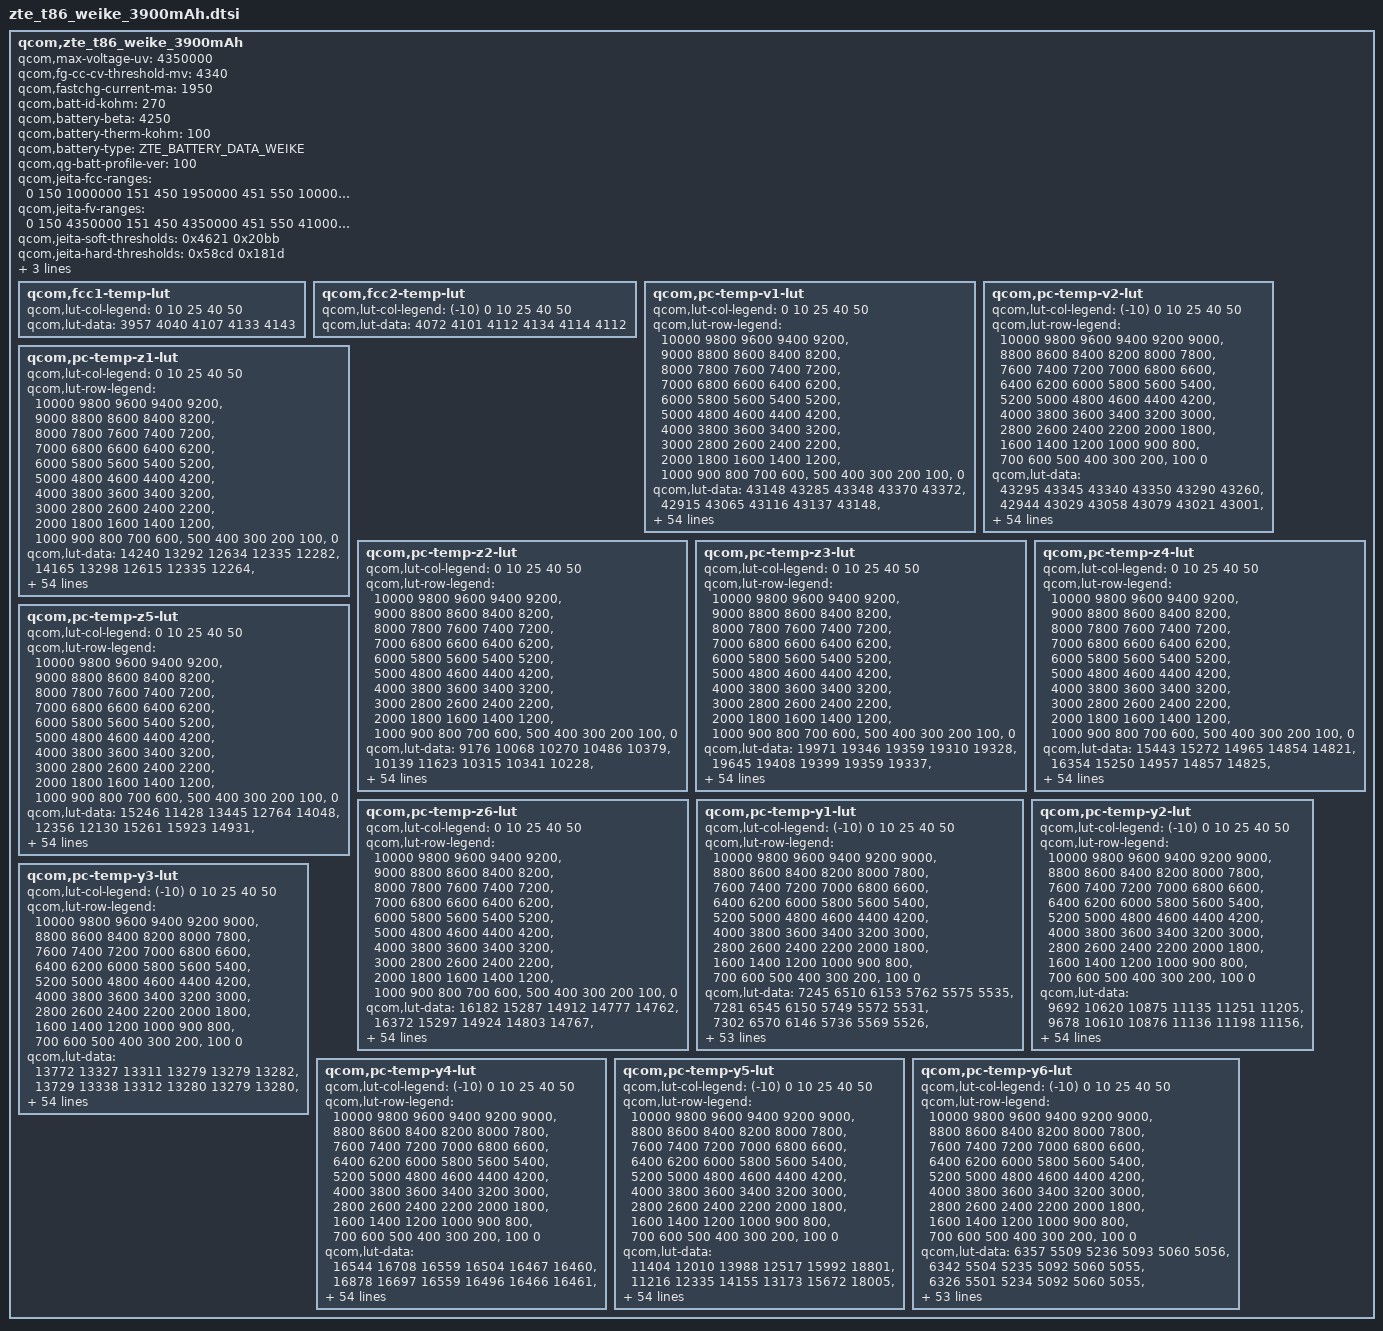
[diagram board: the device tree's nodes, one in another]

qcom,zte_t86_weike_3900mAh {
	/* 4170286_ZTE_T86_3990mAH_PMI632_averaged_MasterSlave_Aug27th2019 */
	qcom,max-voltage-uv = <4350000>;
	qcom,fg-cc-cv-threshold-mv = <4340>;
	qcom,fastchg-current-ma = <1950>;
	qcom,batt-id-kohm = <270>;
	qcom,battery-beta = <4250>;
	qcom,battery-therm-kohm = <100>;
	qcom,battery-type = "ZTE_BATTERY_DATA_WEIKE";
	qcom,qg-batt-profile-ver = <100>;

	qcom,jeita-fcc-ranges = <0   150   1000000
				 151 450  1950000
				 451 550  1000000>;
	qcom,jeita-fv-ranges =  <0   150  4350000
				 151 450  4350000
				 451 550  4100000>;

	/* COOL = 15 DegC, WARM = 45 DegC */
	qcom,jeita-soft-thresholds = <0x4621 0x20bb>;
	/* COLD = 0 DegC, HOT = 55 DegC */
	qcom,jeita-hard-thresholds = <0x58cd 0x181d>;
	/* COOL hys = 17 DegC, WARM hys = 43 DegC */
	qcom,jeita-soft-hys-thresholds = <0x4365 0x22b8>;
	qcom,jeita-soft-fcc-ua = <1000000 1000000>;
	qcom,jeita-soft-fv-uv = <4350000 4100000>;

	qcom,fcc1-temp-lut {
		qcom,lut-col-legend = <0 10 25 40 50>;
		qcom,lut-data = <3957 4040 4107 4133 4143>;
	};

	qcom,fcc2-temp-lut {
		qcom,lut-col-legend = <(-10) 0 10 25 40 50>;
		qcom,lut-data = <4072 4101 4112 4134 4114 4112>;
	};

	qcom,pc-temp-v1-lut {
		qcom,lut-col-legend = <0 10 25 40 50>;
		qcom,lut-row-legend = <10000 9800 9600 9400 9200>,
			<9000 8800 8600 8400 8200>,
			<8000 7800 7600 7400 7200>,
			<7000 6800 6600 6400 6200>,
			<6000 5800 5600 5400 5200>,
			<5000 4800 4600 4400 4200>,
			<4000 3800 3600 3400 3200>,
			<3000 2800 2600 2400 2200>,
			<2000 1800 1600 1400 1200>,
			<1000 900 800 700 600>,
			<500 400 300 200 100>,
			<0>;
		qcom,lut-data = <43148 43285 43348 43370 43372>,
			<42915 43065 43116 43137 43148>,
			<42660 42817 42879 42905 42919>,
			<42429 42577 42644 42677 42689>,
			<42213 42343 42420 42451 42463>,
			<42007 42124 42200 42225 42239>,
			<41804 41919 41978 42002 42017>,
			<41601 41713 41758 41782 41798>,
			<41408 41499 41543 41567 41581>,
			<41242 41301 41330 41354 41367>,
			<41086 41142 41139 41147 41158>,
			<40883 40990 40978 40947 40956>,
			<40598 40767 40802 40750 40759>,
			<40319 40458 40547 40555 40567>,
			<40102 40203 40268 40361 40379>,
			<39921 40028 40089 40182 40199>,
			<39783 39884 39965 40019 40029>,
			<39676 39761 39839 39863 39866>,
			<39574 39654 39702 39717 39718>,
			<39463 39536 39557 39570 39574>,
			<39350 39402 39403 39393 39402>,
			<39236 39256 39236 39187 39200>,
			<39118 39084 39041 38996 39010>,
			<39004 38894 38796 38819 38835>,
			<38898 38731 38621 38670 38683>,
			<38797 38579 38533 38564 38568>,
			<38700 38468 38466 38476 38473>,
			<38604 38393 38395 38389 38384>,
			<38518 38336 38326 38304 38300>,
			<38443 38290 38263 38229 38224>,
			<38378 38250 38206 38165 38155>,
			<38325 38215 38154 38108 38091>,
			<38280 38182 38109 38057 38035>,
			<38240 38152 38068 38010 37982>,
			<38205 38125 38031 37963 37930>,
			<38170 38098 37996 37917 37876>,
			<38135 38066 37958 37870 37820>,
			<38099 38029 37916 37823 37766>,
			<38051 37980 37864 37769 37704>,
			<37981 37901 37787 37691 37622>,
			<37890 37796 37680 37585 37518>,
			<37771 37677 37564 37468 37401>,
			<37627 37537 37430 37332 37264>,
			<37472 37383 37280 37185 37117>,
			<37333 37243 37140 37047 36983>,
			<37233 37153 37055 36968 36910>,
			<37197 37125 37034 36946 36888>,
			<37172 37106 37018 36929 36870>,
			<37144 37086 37000 36913 36852>,
			<37104 37050 36957 36860 36790>,
			<36926 36852 36738 36613 36526>,
			<36510 36434 36312 36174 36081>,
			<35942 35869 35743 35602 35508>,
			<35174 35101 34967 34819 34724>,
			<33972 33914 33761 33611 33510>,
			<30000 30000 30000 30000 30000>;
	};

	qcom,pc-temp-v2-lut {
		qcom,lut-col-legend = <(-10) 0 10 25 40 50>;
		qcom,lut-row-legend = <10000 9800 9600 9400 9200 9000>,
			<8800 8600 8400 8200 8000 7800>,
			<7600 7400 7200 7000 6800 6600>,
			<6400 6200 6000 5800 5600 5400>,
			<5200 5000 4800 4600 4400 4200>,
			<4000 3800 3600 3400 3200 3000>,
			<2800 2600 2400 2200 2000 1800>,
			<1600 1400 1200 1000 900 800>,
			<700 600 500 400 300 200>,
			<100 0>;
		qcom,lut-data = <43295 43345 43340 43350 43290 43260>,
			<42944 43029 43058 43079 43021 43001>,
			<42626 42740 42794 42821 42766 42753>,
			<42343 42481 42549 42580 42526 42517>,
			<42092 42247 42322 42353 42300 42292>,
			<41850 42024 42100 42130 42077 42070>,
			<41609 41809 41881 41906 41855 41848>,
			<41386 41599 41667 41687 41637 41630>,
			<41201 41383 41453 41471 41422 41415>,
			<41037 41171 41243 41260 41210 41203>,
			<40874 40999 41056 41056 41003 40996>,
			<40724 40867 40891 40860 40801 40793>,
			<40527 40697 40700 40655 40603 40596>,
			<40122 40398 40437 40427 40410 40405>,
			<39669 40067 40168 40212 40223 40220>,
			<39451 39829 39965 40036 40048 40045>,
			<39321 39633 39793 39882 39883 39877>,
			<39185 39458 39627 39736 39726 39717>,
			<39026 39304 39470 39601 39580 39569>,
			<38869 39155 39305 39444 39422 39410>,
			<38722 38989 39108 39230 39226 39219>,
			<38581 38826 38909 39005 39017 39015>,
			<38454 38682 38750 38817 38827 38827>,
			<38333 38553 38614 38647 38647 38646>,
			<38233 38435 38494 38514 38506 38503>,
			<38157 38325 38388 38407 38398 38395>,
			<38093 38226 38292 38312 38305 38302>,
			<38036 38135 38203 38223 38217 38212>,
			<37984 38052 38122 38142 38136 38130>,
			<37937 37982 38048 38070 38064 38055>,
			<37892 37921 37982 38005 37999 37987>,
			<37849 37871 37919 37943 37937 37924>,
			<37805 37833 37859 37884 37884 37871>,
			<37761 37799 37804 37826 37827 37815>,
			<37712 37765 37761 37771 37760 37740>,
			<37660 37731 37724 37715 37683 37648>,
			<37604 37690 37682 37653 37602 37554>,
			<37544 37642 37635 37588 37513 37452>,
			<37479 37584 37579 37520 37429 37360>,
			<37408 37515 37513 37452 37358 37288>,
			<37330 37435 37435 37374 37282 37213>,
			<37248 37338 37335 37280 37192 37121>,
			<37165 37214 37217 37161 37075 37002>,
			<37079 37094 37076 37027 36945 36868>,
			<36980 36991 36961 36904 36827 36765>,
			<36876 36911 36919 36872 36800 36743>,
			<36821 36878 36898 36863 36789 36733>,
			<36755 36839 36878 36843 36774 36716>,
			<36666 36785 36842 36814 36748 36682>,
			<36528 36676 36744 36720 36654 36553>,
			<36279 36444 36441 36406 36333 36178>,
			<35859 35991 35918 35893 35830 35658>,
			<35232 35337 35230 35217 35178 34975>,
			<34302 34419 34257 34250 34253 34004>,
			<32614 32924 32845 32827 32895 32598>,
			<29817 28642 28556 28034 28094 28150>;
	};

	qcom,pc-temp-z1-lut {
		qcom,lut-col-legend = <0 10 25 40 50>;
		qcom,lut-row-legend = <10000 9800 9600 9400 9200>,
			<9000 8800 8600 8400 8200>,
			<8000 7800 7600 7400 7200>,
			<7000 6800 6600 6400 6200>,
			<6000 5800 5600 5400 5200>,
			<5000 4800 4600 4400 4200>,
			<4000 3800 3600 3400 3200>,
			<3000 2800 2600 2400 2200>,
			<2000 1800 1600 1400 1200>,
			<1000 900 800 700 600>,
			<500 400 300 200 100>,
			<0>;
		qcom,lut-data = <14240 13292 12634 12335 12282>,
			<14165 13298 12615 12335 12264>,
			<14177 13295 12593 12331 12258>,
			<14185 13277 12581 12325 12262>,
			<14174 13251 12579 12323 12261>,
			<14158 13249 12575 12323 12260>,
			<14145 13249 12569 12323 12262>,
			<14137 13248 12565 12323 12264>,
			<14133 13237 12566 12324 12268>,
			<14147 13227 12569 12326 12274>,
			<14165 13220 12572 12328 12278>,
			<14158 13209 12572 12329 12276>,
			<14088 13185 12570 12330 12274>,
			<14007 13131 12554 12329 12274>,
			<13959 13107 12533 12327 12274>,
			<13927 13109 12532 12327 12274>,
			<13927 13113 12542 12327 12273>,
			<13941 13126 12551 12327 12272>,
			<13951 13149 12556 12328 12272>,
			<13961 13164 12560 12329 12272>,
			<13973 13179 12562 12328 12273>,
			<13972 13189 12564 12327 12275>,
			<13954 13189 12565 12326 12275>,
			<13951 13188 12568 12327 12275>,
			<13971 13192 12570 12329 12275>,
			<13989 13202 12572 12330 12277>,
			<13989 13208 12576 12333 12280>,
			<13986 13206 12579 12337 12282>,
			<13985 13203 12584 12341 12284>,
			<13984 13208 12589 12345 12285>,
			<13985 13218 12592 12347 12287>,
			<14002 13227 12596 12349 12289>,
			<14041 13237 12601 12352 12291>,
			<14055 13245 12607 12355 12293>,
			<14046 13254 12613 12359 12296>,
			<14037 13267 12619 12363 12299>,
			<14039 13280 12626 12366 12301>,
			<14049 13295 12633 12369 12303>,
			<14063 13306 12639 12371 12304>,
			<14097 13313 12644 12372 12305>,
			<14123 13320 12649 12374 12307>,
			<14126 13329 12652 12376 12307>,
			<14128 13344 12656 12378 12309>,
			<14139 13368 12659 12379 12310>,
			<14150 13378 12662 12378 12311>,
			<14171 13346 12665 12377 12305>,
			<14140 13345 12662 12377 12304>,
			<14126 13343 12664 12378 12305>,
			<14121 13348 12672 12380 12307>,
			<14135 13355 12675 12383 12309>,
			<14176 13390 12682 12388 12313>,
			<14179 13408 12691 12396 12318>,
			<14189 13408 12708 12404 12327>,
			<14207 13464 12730 12418 12339>,
			<14207 13464 12730 12418 12339>,
			<14207 13464 12730 12418 12339>;
	};

	qcom,pc-temp-z2-lut {
		qcom,lut-col-legend = <0 10 25 40 50>;
		qcom,lut-row-legend = <10000 9800 9600 9400 9200>,
			<9000 8800 8600 8400 8200>,
			<8000 7800 7600 7400 7200>,
			<7000 6800 6600 6400 6200>,
			<6000 5800 5600 5400 5200>,
			<5000 4800 4600 4400 4200>,
			<4000 3800 3600 3400 3200>,
			<3000 2800 2600 2400 2200>,
			<2000 1800 1600 1400 1200>,
			<1000 900 800 700 600>,
			<500 400 300 200 100>,
			<0>;
		qcom,lut-data = <9176 10068 10270 10486 10379>,
			<10139 11623 10315 10341 10228>,
			<9947 10936 10345 10348 10191>,
			<9982 10589 10453 10412 10296>,
			<9986 10158 10710 10407 10340>,
			<9986 10153 10868 10398 10378>,
			<9987 10272 10817 10384 10378>,
			<9991 10303 10739 10370 10351>,
			<9994 10165 10707 10363 10332>,
			<9984 10048 10691 10315 10316>,
			<9969 10094 10673 10281 10294>,
			<9962 10187 10654 10285 10234>,
			<9955 10194 10627 10292 10165>,
			<9946 10113 10538 10283 10167>,
			<9936 10065 10393 10258 10203>,
			<9923 10069 10333 10248 10226>,
			<9915 10078 10293 10238 10234>,
			<9909 10091 10280 10232 10242>,
			<9906 10113 10309 10242 10257>,
			<9904 10132 10346 10269 10276>,
			<9904 10150 10372 10345 10314>,
			<9906 10164 10401 10517 10422>,
			<9907 10178 10402 10568 10473>,
			<9909 10190 10360 10414 10415>,
			<9914 10190 10330 10285 10355>,
			<9923 10188 10330 10322 10379>,
			<9933 10187 10341 10397 10435>,
			<9946 10200 10358 10428 10424>,
			<9957 10216 10382 10454 10301>,
			<9964 10219 10396 10439 10228>,
			<9970 10220 10396 10365 10189>,
			<9976 10220 10392 10285 10151>,
			<9982 10220 10385 10233 10144>,
			<9986 10222 10376 10193 10146>,
			<9991 10232 10378 10198 10162>,
			<9998 10245 10389 10258 10223>,
			<10006 10255 10404 10305 10285>,
			<10017 10263 10432 10345 10344>,
			<10028 10272 10464 10378 10389>,
			<10039 10285 10494 10386 10396>,
			<10050 10298 10519 10397 10393>,
			<10057 10303 10522 10415 10392>,
			<10065 10307 10510 10459 10393>,
			<10096 10314 10511 10459 10393>,
			<10062 10357 10521 10436 10394>,
			<9882 10490 10540 10439 10387>,
			<9866 10519 10511 10447 10375>,
			<9744 10699 10508 10427 10376>,
			<9847 10807 10528 10455 10436>,
			<9841 10897 10559 10566 10501>,
			<9713 10618 10614 10457 10333>,
			<9664 10574 10591 10308 10167>,
			<9647 10516 10501 10241 10099>,
			<9614 10351 10448 10172 10035>,
			<9614 10351 10448 10172 10035>,
			<9614 10351 10448 10172 10035>;
	};

	qcom,pc-temp-z3-lut {
		qcom,lut-col-legend = <0 10 25 40 50>;
		qcom,lut-row-legend = <10000 9800 9600 9400 9200>,
			<9000 8800 8600 8400 8200>,
			<8000 7800 7600 7400 7200>,
			<7000 6800 6600 6400 6200>,
			<6000 5800 5600 5400 5200>,
			<5000 4800 4600 4400 4200>,
			<4000 3800 3600 3400 3200>,
			<3000 2800 2600 2400 2200>,
			<2000 1800 1600 1400 1200>,
			<1000 900 800 700 600>,
			<500 400 300 200 100>,
			<0>;
		qcom,lut-data = <19971 19346 19359 19310 19328>,
			<19645 19408 19399 19359 19337>,
			<19767 19525 19416 19368 19348>,
			<19812 19576 19457 19398 19382>,
			<19807 19620 19462 19405 19393>,
			<19794 19628 19465 19409 19398>,
			<19790 19629 19469 19410 19400>,
			<19787 19629 19471 19411 19402>,
			<19783 19623 19474 19411 19402>,
			<19777 19617 19476 19404 19400>,
			<19763 19611 19475 19398 19396>,
			<19763 19605 19462 19392 19389>,
			<19798 19606 19449 19386 19379>,
			<19826 19604 19450 19383 19375>,
			<19814 19596 19452 19381 19372>,
			<19785 19578 19440 19378 19370>,
			<19756 19557 19414 19371 19366>,
			<19725 19537 19402 19364 19363>,
			<19701 19517 19403 19360 19356>,
			<19687 19512 19405 19358 19348>,
			<19678 19516 19409 19362 19350>,
			<19676 19522 19418 19378 19360>,
			<19686 19532 19422 19382 19365>,
			<19696 19545 19421 19366 19351>,
			<19702 19551 19418 19350 19337>,
			<19709 19553 19411 19351 19349>,
			<19713 19553 19405 19359 19375>,
			<19718 19551 19406 19370 19385>,
			<19721 19548 19413 19392 19389>,
			<19721 19545 19418 19401 19388>,
			<19719 19542 19424 19397 19384>,
			<19715 19539 19427 19391 19378>,
			<19707 19534 19426 19386 19373>,
			<19698 19530 19424 19380 19367>,
			<19689 19526 19422 19375 19361>,
			<19677 19520 19418 19369 19354>,
			<19657 19516 19415 19365 19349>,
			<19628 19511 19413 19362 19347>,
			<19608 19507 19410 19359 19346>,
			<19592 19504 19408 19358 19346>,
			<19583 19502 19405 19358 19346>,
			<19589 19500 19403 19358 19348>,
			<19595 19498 19401 19361 19352>,
			<19582 19494 19399 19361 19354>,
			<19494 19477 19394 19357 19354>,
			<19316 19406 19381 19347 19341>,
			<19309 19365 19373 19343 19334>,
			<19274 19321 19362 19340 19331>,
			<19297 19305 19358 19331 19320>,
			<19273 19301 19354 19324 19316>,
			<19274 19347 19349 19342 19343>,
			<19277 19350 19348 19356 19352>,
			<19321 19341 19355 19359 19354>,
			<19324 19334 19355 19359 19359>,
			<19324 19334 19355 19359 19359>,
			<19324 19334 19355 19359 19359>;
	};

	qcom,pc-temp-z4-lut {
		qcom,lut-col-legend = <0 10 25 40 50>;
		qcom,lut-row-legend = <10000 9800 9600 9400 9200>,
			<9000 8800 8600 8400 8200>,
			<8000 7800 7600 7400 7200>,
			<7000 6800 6600 6400 6200>,
			<6000 5800 5600 5400 5200>,
			<5000 4800 4600 4400 4200>,
			<4000 3800 3600 3400 3200>,
			<3000 2800 2600 2400 2200>,
			<2000 1800 1600 1400 1200>,
			<1000 900 800 700 600>,
			<500 400 300 200 100>,
			<0>;
		qcom,lut-data = <15443 15272 14965 14854 14821>,
			<16354 15250 14957 14857 14825>,
			<16318 15431 14896 14811 14800>,
			<16199 15330 14994 14885 14855>,
			<16037 15199 14928 14860 14839>,
			<15850 15100 14862 14823 14806>,
			<15706 15006 14824 14798 14784>,
			<15594 14952 14793 14776 14765>,
			<15491 14924 14767 14758 14748>,
			<15388 14897 14745 14743 14731>,
			<15293 14850 14725 14731 14719>,
			<15218 14791 14704 14722 14715>,
			<15157 14774 14692 14714 14712>,
			<15107 14784 14705 14708 14706>,
			<15065 14787 14730 14703 14699>,
			<15028 14771 14731 14698 14692>,
			<14996 14755 14716 14693 14686>,
			<14967 14746 14702 14687 14681>,
			<14944 14739 14691 14681 14677>,
			<14925 14732 14684 14676 14674>,
			<14909 14723 14687 14683 14680>,
			<14890 14716 14697 14715 14713>,
			<14867 14733 14725 14754 14751>,
			<14847 14772 14815 14812 14802>,
			<14832 14794 14864 14848 14836>,
			<14818 14829 14853 14837 14817>,
			<14809 14845 14833 14809 14771>,
			<14805 14837 14811 14780 14744>,
			<14802 14823 14786 14742 14723>,
			<14798 14809 14763 14718 14710>,
			<14795 14789 14742 14707 14701>,
			<14790 14772 14724 14700 14694>,
			<14783 14757 14712 14693 14688>,
			<14775 14744 14703 14687 14683>,
			<14767 14731 14697 14687 14682>,
			<14761 14720 14693 14690 14686>,
			<14763 14712 14691 14691 14689>,
			<14771 14704 14690 14691 14691>,
			<14776 14701 14689 14690 14693>,
			<14776 14702 14692 14694 14697>,
			<14773 14703 14699 14703 14702>,
			<14762 14702 14699 14704 14703>,
			<14748 14698 14694 14698 14699>,
			<14748 14696 14693 14698 14699>,
			<14800 14694 14690 14701 14701>,
			<14934 14714 14660 14670 14671>,
			<14937 14755 14658 14663 14666>,
			<14966 14797 14655 14647 14649>,
			<14936 14808 14648 14638 14637>,
			<14953 14807 14651 14641 14637>,
			<14952 14766 14678 14654 14649>,
			<14972 14777 14693 14656 14657>,
			<14941 14797 14690 14658 14660>,
			<14960 14820 14696 14662 14657>,
			<14960 14820 14696 14662 14657>,
			<14960 14820 14696 14662 14657>;
	};

	qcom,pc-temp-z5-lut {
		qcom,lut-col-legend = <0 10 25 40 50>;
		qcom,lut-row-legend = <10000 9800 9600 9400 9200>,
			<9000 8800 8600 8400 8200>,
			<8000 7800 7600 7400 7200>,
			<7000 6800 6600 6400 6200>,
			<6000 5800 5600 5400 5200>,
			<5000 4800 4600 4400 4200>,
			<4000 3800 3600 3400 3200>,
			<3000 2800 2600 2400 2200>,
			<2000 1800 1600 1400 1200>,
			<1000 900 800 700 600>,
			<500 400 300 200 100>,
			<0>;
		qcom,lut-data = <15246 11428 13445 12764 14048>,
			<12356 12130 15261 15923 14931>,
			<13158 13501 16862 17289 16255>,
			<13574 14544 17064 17680 18028>,
			<13841 15741 17266 18110 19002>,
			<14055 16207 17524 18786 19860>,
			<14296 16470 18247 19389 20609>,
			<14613 16872 19464 20030 21276>,
			<14899 17476 20860 20403 22009>,
			<15020 18045 22522 20465 22974>,
			<15120 19238 23946 20385 23495>,
			<15509 20913 25475 20394 22772>,
			<17323 21940 26466 20602 21710>,
			<18892 23766 27280 21231 21816>,
			<18803 24306 27475 22225 22804>,
			<18329 23325 25225 22488 23702>,
			<17821 21955 21108 21943 24605>,
			<17128 20938 19572 21505 25123>,
			<16666 20058 21536 21884 24611>,
			<16640 20010 24480 22898 23776>,
			<16721 22297 28609 26788 24905>,
			<17079 26075 34597 35935 30071>,
			<19297 32666 36621 38390 32004>,
			<21836 41151 34202 28038 24348>,
			<23583 44840 31177 18767 16979>,
			<25306 45046 26531 17392 17273>,
			<27547 43258 21969 16730 18766>,
			<30906 40164 21164 17542 19456>,
			<33157 36963 21260 20969 20903>,
			<34001 35097 21980 23371 22020>,
			<34643 33526 24011 24307 22985>,
			<34708 32291 26480 25126 24158>,
			<33365 31517 29005 26390 25490>,
			<31648 31196 31526 27827 26823>,
			<30187 30905 33367 28800 27198>,
			<28593 30487 35008 29803 27294>,
			<25813 30327 35590 30086 27316>,
			<21784 30433 35619 29284 27116>,
			<19661 30695 35542 28189 26682>,
			<19177 31161 34462 26915 25538>,
			<19254 31658 32220 25098 23606>,
			<20608 31775 30914 24572 23268>,
			<22147 31628 30112 25237 24359>,
			<21624 30942 28949 24656 24506>,
			<17807 27681 27646 23355 24045>,
			<11689 18061 27728 23024 22319>,
			<11553 14353 24605 21830 20072>,
			<11150 12391 21242 23134 21374>,
			<11358 11983 21286 22396 21307>,
			<11157 11966 20280 19458 20080>,
			<11211 13582 17375 20257 22164>,
			<11226 13326 15889 20848 21543>,
			<11634 12823 16149 19982 19556>,
			<11536 12376 15483 18459 18906>,
			<11536 12376 15483 18459 18906>,
			<11536 12376 15483 18459 18906>;
	};

	qcom,pc-temp-z6-lut {
		qcom,lut-col-legend = <0 10 25 40 50>;
		qcom,lut-row-legend = <10000 9800 9600 9400 9200>,
			<9000 8800 8600 8400 8200>,
			<8000 7800 7600 7400 7200>,
			<7000 6800 6600 6400 6200>,
			<6000 5800 5600 5400 5200>,
			<5000 4800 4600 4400 4200>,
			<4000 3800 3600 3400 3200>,
			<3000 2800 2600 2400 2200>,
			<2000 1800 1600 1400 1200>,
			<1000 900 800 700 600>,
			<500 400 300 200 100>,
			<0>;
		qcom,lut-data = <16182 15287 14912 14777 14762>,
			<16372 15297 14924 14803 14767>,
			<16384 15416 14904 14787 14762>,
			<16340 15385 14965 14834 14803>,
			<16256 15343 14938 14826 14800>,
			<16144 15302 14912 14814 14792>,
			<16059 15255 14896 14805 14785>,
			<15994 15222 14883 14797 14779>,
			<15934 15202 14874 14788 14772>,
			<15869 15181 14866 14780 14765>,
			<15806 15150 14856 14771 14758>,
			<15754 15118 14837 14764 14751>,
			<15713 15099 14826 14757 14745>,
			<15675 15087 14829 14753 14739>,
			<15633 15075 14834 14749 14734>,
			<15591 15058 14831 14744 14730>,
			<15556 15042 14812 14738 14725>,
			<15527 15031 14800 14732 14720>,
			<15505 15022 14796 14727 14715>,
			<15489 15020 14795 14724 14709>,
			<15476 15021 14798 14729 14713>,
			<15468 15023 14807 14751 14733>,
			<15464 15036 14823 14770 14751>,
			<15462 15060 14861 14786 14766>,
			<15459 15075 14881 14795 14775>,
			<15457 15092 14874 14791 14773>,
			<15458 15100 14863 14784 14768>,
			<15462 15097 14855 14778 14762>,
			<15465 15091 14849 14774 14756>,
			<15466 15085 14843 14770 14750>,
			<15467 15077 14838 14763 14744>,
			<15466 15069 14833 14757 14739>,
			<15463 15063 14828 14751 14733>,
			<15460 15057 14824 14745 14728>,
			<15456 15053 14821 14743 14724>,
			<15453 15049 14818 14741 14722>,
			<15449 15047 14816 14740 14721>,
			<15446 15046 14815 14738 14720>,
			<15445 15046 14815 14736 14720>,
			<15448 15048 14816 14737 14721>,
			<15452 15052 14819 14741 14724>,
			<15459 15055 14819 14742 14725>,
			<15467 15058 14817 14740 14726>,
			<15471 15059 14817 14740 14727>,
			<15462 15055 14814 14740 14728>,
			<15439 15034 14796 14722 14707>,
			<15437 15031 14790 14716 14701>,
			<15434 15026 14784 14708 14693>,
			<15434 15026 14780 14698 14681>,
			<15439 15028 14781 14697 14679>,
			<15449 15040 14792 14714 14699>,
			<15467 15054 14801 14724 14710>,
			<15488 15067 14807 14728 14714>,
			<15521 15089 14816 14734 14719>,
			<15521 15089 14816 14734 14719>,
			<15521 15089 14816 14734 14719>;
	};

	qcom,pc-temp-y1-lut {
		qcom,lut-col-legend = <(-10) 0 10 25 40 50>;
		qcom,lut-row-legend = <10000 9800 9600 9400 9200 9000>,
			<8800 8600 8400 8200 8000 7800>,
			<7600 7400 7200 7000 6800 6600>,
			<6400 6200 6000 5800 5600 5400>,
			<5200 5000 4800 4600 4400 4200>,
			<4000 3800 3600 3400 3200 3000>,
			<2800 2600 2400 2200 2000 1800>,
			<1600 1400 1200 1000 900 800>,
			<700 600 500 400 300 200>,
			<100 0>;
		qcom,lut-data = <7245 6510 6153 5762 5575 5535>,
			<7281 6545 6150 5749 5572 5531>,
			<7302 6570 6146 5736 5569 5526>,
			<7313 6587 6141 5725 5566 5522>,
			<7316 6596 6135 5717 5564 5520>,
			<7315 6596 6129 5714 5563 5520>,
			<7279 6584 6120 5716 5564 5521>,
			<7243 6572 6114 5717 5564 5522>,
			<7247 6572 6113 5715 5563 5520>,
			<7261 6571 6114 5712 5562 5515>,
			<7264 6566 6113 5709 5561 5515>,
			<7261 6550 6110 5706 5559 5518>,
			<7260 6541 6109 5704 5558 5519>,
			<7278 6561 6108 5702 5558 5519>,
			<7301 6586 6108 5702 5558 5519>,
			<7302 6594 6113 5704 5558 5519>,
			<7295 6599 6123 5710 5556 5520>,
			<7289 6600 6124 5711 5556 5520>,
			<7280 6599 6120 5708 5557 5518>,
			<7270 6597 6116 5707 5558 5516>,
			<7265 6592 6115 5706 5559 5517>,
			<7261 6585 6115 5705 5561 5517>,
			<7261 6585 6114 5707 5561 5518>,
			<7260 6586 6112 5712 5560 5519>,
			<7261 6586 6110 5714 5560 5520>,
			<7266 6584 6110 5714 5561 5521>,
			<7270 6581 6109 5714 5561 5522>,
			<7264 6584 6110 5716 5562 5521>,
			<7247 6589 6110 5717 5564 5520>,
			<7241 6590 6113 5719 5565 5521>,
			<7242 6590 6119 5721 5567 5525>,
			<7244 6588 6123 5723 5568 5529>,
			<7242 6583 6119 5727 5570 5531>,
			<7239 6577 6115 5730 5571 5533>,
			<7235 6573 6113 5733 5574 5532>,
			<7230 6568 6111 5735 5576 5531>,
			<7223 6567 6110 5736 5577 5531>,
			<7209 6577 6109 5738 5576 5532>,
			<7198 6586 6109 5739 5576 5533>,
			<7210 6583 6109 5741 5579 5533>,
			<7232 6580 6109 5742 5580 5534>,
			<7210 6578 6117 5741 5581 5536>,
			<7195 6577 6124 5750 5582 5537>,
			<7220 6599 6129 5746 5585 5536>,
			<7260 6595 6130 5749 5586 5540>,
			<7259 6587 6132 5755 5587 5541>,
			<7237 6603 6125 5756 5586 5541>,
			<7290 6604 6137 5758 5588 5542>,
			<7254 6595 6134 5754 5586 5542>,
			<7266 6588 6138 5758 5590 5541>,
			<7255 6595 6141 5762 5592 5543>,
			<7248 6619 6151 5771 5595 5550>,
			<7294 6635 6185 5784 5602 5558>,
			<7304 6636 6215 5804 5612 5567>,
			<7304 6636 6215 5804 5612 5567>,
			<7304 6636 6215 5804 5612 5567>;
	};

	qcom,pc-temp-y2-lut {
		qcom,lut-col-legend = <(-10) 0 10 25 40 50>;
		qcom,lut-row-legend = <10000 9800 9600 9400 9200 9000>,
			<8800 8600 8400 8200 8000 7800>,
			<7600 7400 7200 7000 6800 6600>,
			<6400 6200 6000 5800 5600 5400>,
			<5200 5000 4800 4600 4400 4200>,
			<4000 3800 3600 3400 3200 3000>,
			<2800 2600 2400 2200 2000 1800>,
			<1600 1400 1200 1000 900 800>,
			<700 600 500 400 300 200>,
			<100 0>;
		qcom,lut-data = <9692 10620 10875 11135 11251 11205>,
			<9678 10610 10876 11136 11198 11156>,
			<9671 10592 10863 11119 11120 11076>,
			<9672 10573 10843 11091 11039 10990>,
			<9679 10557 10821 11059 10980 10923>,
			<9700 10550 10801 11026 10964 10897>,
			<9891 10547 10773 10981 10974 10887>,
			<10103 10544 10750 10939 10982 10882>,
			<10139 10546 10740 10909 10955 10891>,
			<10105 10552 10731 10885 10905 10907>,
			<10126 10564 10719 10875 10897 10905>,
			<10290 10601 10705 10873 10903 10882>,
			<10371 10633 10700 10873 10905 10868>,
			<10095 10653 10731 10879 10869 10870>,
			<9739 10669 10778 10885 10834 10873>,
			<9698 10684 10815 10891 10844 10862>,
			<9698 10700 10848 10908 10870 10840>,
			<9698 10718 10858 10939 10905 10839>,
			<9693 10741 10860 11012 10964 10850>,
			<9687 10765 10862 11046 10999 10869>,
			<9684 10787 10885 11013 10997 10959>,
			<9682 10809 10928 10976 10991 11062>,
			<9680 10837 10974 11010 11000 11069>,
			<9679 10874 11033 11104 11032 11059>,
			<9678 10887 11069 11155 11055 11056>,
			<9676 10844 11098 11180 11083 11077>,
			<9673 10801 11115 11193 11110 11106>,
			<9672 10799 11115 11197 11131 11132>,
			<9670 10811 11114 11200 11156 11161>,
			<9669 10837 11113 11205 11186 11181>,
			<9667 10933 11109 11212 11231 11198>,
			<9666 10967 11109 11214 11256 11196>,
			<9664 10720 11114 11230 11258 11174>,
			<9662 10463 11119 11243 11249 11151>,
			<9661 10550 11109 11237 11215 11151>,
			<9660 10784 11083 11232 11163 11177>,
			<9659 10808 11064 11229 11149 11184>,
			<9657 10562 11047 11217 11161 11148>,
			<9657 10338 11038 11204 11166 11116>,
			<9656 10259 11022 11193 11122 11069>,
			<9655 10257 11015 11190 11096 11047>,
			<9655 10186 11001 11216 11162 11027>,
			<9654 9894 10968 11152 11094 11099>,
			<9654 9738 10967 11211 11109 11085>,
			<9654 9708 10861 11173 11087 11086>,
			<9653 9681 10798 11106 11031 10928>,
			<9653 9676 10750 11148 11036 10912>,
			<9653 9671 10709 11098 11005 10831>,
			<9653 9669 10705 11117 11015 10890>,
			<9653 9666 10698 11113 10996 10889>,
			<9653 9664 10627 11067 10948 10790>,
			<9653 9661 10534 10981 10890 10711>,
			<9652 9658 10431 10916 10792 10643>,
			<9652 9655 10349 10793 10668 10459>,
			<9652 9655 10349 10793 10668 10459>,
			<9652 9655 10349 10793 10668 10459>;
	};

	qcom,pc-temp-y3-lut {
		qcom,lut-col-legend = <(-10) 0 10 25 40 50>;
		qcom,lut-row-legend = <10000 9800 9600 9400 9200 9000>,
			<8800 8600 8400 8200 8000 7800>,
			<7600 7400 7200 7000 6800 6600>,
			<6400 6200 6000 5800 5600 5400>,
			<5200 5000 4800 4600 4400 4200>,
			<4000 3800 3600 3400 3200 3000>,
			<2800 2600 2400 2200 2000 1800>,
			<1600 1400 1200 1000 900 800>,
			<700 600 500 400 300 200>,
			<100 0>;
		qcom,lut-data = <13772 13327 13311 13279 13279 13282>,
			<13729 13338 13312 13280 13279 13280>,
			<13684 13349 13313 13282 13278 13279>,
			<13643 13359 13315 13284 13279 13278>,
			<13615 13368 13316 13284 13279 13278>,
			<13607 13376 13318 13285 13279 13278>,
			<13617 13383 13319 13284 13281 13279>,
			<13627 13387 13321 13284 13281 13280>,
			<13593 13390 13326 13287 13281 13280>,
			<13519 13391 13332 13292 13281 13280>,
			<13495 13396 13337 13294 13281 13280>,
			<13491 13407 13341 13294 13282 13279>,
			<13486 13412 13342 13294 13282 13279>,
			<13466 13403 13340 13293 13285 13280>,
			<13444 13389 13337 13293 13286 13280>,
			<13441 13382 13337 13296 13286 13281>,
			<13441 13377 13339 13302 13286 13283>,
			<13440 13373 13339 13304 13287 13285>,
			<13433 13368 13335 13304 13290 13287>,
			<13422 13364 13330 13304 13292 13287>,
			<13413 13358 13325 13301 13291 13287>,
			<13402 13352 13319 13296 13287 13286>,
			<13392 13346 13312 13292 13284 13283>,
			<13375 13341 13306 13287 13280 13277>,
			<13365 13336 13303 13285 13279 13275>,
			<13373 13324 13302 13284 13278 13275>,
			<13388 13316 13303 13283 13278 13276>,
			<13399 13315 13303 13283 13278 13275>,
			<13409 13312 13303 13283 13278 13275>,
			<13422 13309 13304 13284 13278 13274>,
			<13442 13309 13307 13288 13279 13274>,
			<13467 13309 13309 13289 13279 13274>,
			<13497 13302 13307 13289 13279 13275>,
			<13533 13297 13306 13289 13279 13276>,
			<13574 13308 13306 13289 13279 13276>,
			<13620 13330 13307 13289 13279 13277>,
			<13676 13338 13308 13288 13279 13276>,
			<13746 13335 13307 13287 13279 13275>,
			<13830 13332 13307 13286 13278 13274>,
			<13924 13334 13307 13287 13277 13276>,
			<14033 13341 13308 13287 13277 13277>,
			<14168 13347 13309 13285 13278 13277>,
			<14324 13353 13308 13286 13279 13277>,
			<14386 13351 13304 13285 13278 13277>,
			<14548 13370 13300 13284 13278 13276>,
			<14797 13393 13315 13286 13279 13281>,
			<14933 13424 13318 13291 13283 13285>,
			<15077 13458 13326 13292 13287 13285>,
			<15212 13504 13336 13298 13291 13288>,
			<15341 13564 13343 13299 13290 13287>,
			<15450 13625 13345 13295 13284 13283>,
			<15567 13691 13348 13297 13284 13285>,
			<15728 13837 13364 13302 13291 13290>,
			<15952 14109 13398 13308 13295 13294>,
			<15952 14109 13398 13308 13295 13294>,
			<15952 14109 13398 13308 13295 13294>;
	};

	qcom,pc-temp-y4-lut {
		qcom,lut-col-legend = <(-10) 0 10 25 40 50>;
		qcom,lut-row-legend = <10000 9800 9600 9400 9200 9000>,
			<8800 8600 8400 8200 8000 7800>,
			<7600 7400 7200 7000 6800 6600>,
			<6400 6200 6000 5800 5600 5400>,
			<5200 5000 4800 4600 4400 4200>,
			<4000 3800 3600 3400 3200 3000>,
			<2800 2600 2400 2200 2000 1800>,
			<1600 1400 1200 1000 900 800>,
			<700 600 500 400 300 200>,
			<100 0>;
		qcom,lut-data = <16544 16708 16559 16504 16467 16460>,
			<16878 16697 16559 16496 16466 16461>,
			<17106 16696 16562 16493 16466 16463>,
			<17246 16702 16566 16493 16466 16464>,
			<17314 16713 16571 16494 16467 16465>,
			<17322 16728 16576 16497 16467 16465>,
			<17208 16751 16582 16503 16468 16465>,
			<17096 16774 16589 16509 16470 16465>,
			<17265 16786 16597 16510 16473 16467>,
			<17650 16796 16607 16511 16478 16471>,
			<17793 16839 16623 16515 16482 16475>,
			<17837 16980 16653 16528 16487 16479>,
			<17852 17052 16680 16540 16491 16483>,
			<17521 17010 16699 16548 16495 16488>,
			<17074 16940 16718 16557 16501 16494>,
			<17032 16874 16746 16574 16510 16500>,
			<17063 16805 16778 16600 16522 16507>,
			<17074 16771 16783 16633 16539 16518>,
			<17045 16759 16762 16682 16567 16540>,
			<17002 16744 16733 16702 16582 16553>,
			<16964 16707 16661 16660 16576 16550>,
			<16923 16662 16576 16596 16565 16544>,
			<16888 16639 16553 16543 16537 16525>,
			<16857 16624 16542 16495 16486 16485>,
			<16838 16618 16537 16481 16468 16470>,
			<16827 16626 16534 16481 16468 16468>,
			<16821 16633 16532 16482 16468 16468>,
			<16822 16628 16533 16485 16470 16470>,
			<16826 16619 16534 16488 16475 16476>,
			<16830 16611 16533 16492 16481 16482>,
			<16837 16606 16532 16498 16491 16490>,
			<16843 16606 16531 16503 16501 16499>,
			<16847 16630 16528 16511 16516 16514>,
			<16851 16654 16526 16515 16526 16525>,
			<16856 16643 16528 16512 16522 16520>,
			<16863 16620 16533 16507 16509 16506>,
			<16869 16624 16536 16498 16494 16492>,
			<16876 16658 16539 16484 16475 16478>,
			<16882 16689 16541 16478 16466 16471>,
			<16891 16699 16545 16477 16471 16475>,
			<16905 16702 16547 16480 16476 16480>,
			<16922 16704 16548 16487 16479 16484>,
			<16946 16714 16552 16481 16474 16478>,
			<16941 16708 16537 16480 16474 16471>,
			<16949 16715 16545 16465 16448 16446>,
			<17005 16764 16558 16484 16470 16470>,
			<17049 16799 16578 16497 16487 16499>,
			<17097 16852 16617 16525 16518 16542>,
			<17153 16927 16678 16570 16562 16582>,
			<17209 16990 16743 16593 16570 16558>,
			<17227 17029 16715 16528 16489 16481>,
			<17230 17011 16688 16523 16483 16481>,
			<17257 17053 16748 16551 16495 16493>,
			<17358 17203 16869 16622 16534 16553>,
			<17358 17203 16869 16622 16534 16553>,
			<17358 17203 16869 16622 16534 16553>;
	};

	qcom,pc-temp-y5-lut {
		qcom,lut-col-legend = <(-10) 0 10 25 40 50>;
		qcom,lut-row-legend = <10000 9800 9600 9400 9200 9000>,
			<8800 8600 8400 8200 8000 7800>,
			<7600 7400 7200 7000 6800 6600>,
			<6400 6200 6000 5800 5600 5400>,
			<5200 5000 4800 4600 4400 4200>,
			<4000 3800 3600 3400 3200 3000>,
			<2800 2600 2400 2200 2000 1800>,
			<1600 1400 1200 1000 900 800>,
			<700 600 500 400 300 200>,
			<100 0>;
		qcom,lut-data = <11404 12010 13988 12517 15992 18801>,
			<11216 12335 14155 13173 15672 18005>,
			<11134 12869 14169 13472 15427 17187>,
			<11142 13444 14088 13527 15244 16461>,
			<11226 13896 13966 13448 15108 15943>,
			<11418 14067 13848 13316 15011 15747>,
			<12601 14117 13617 12887 15001 15835>,
			<13689 14140 13449 12560 14972 15900>,
			<13071 14100 13683 13034 14668 15580>,
			<11660 13997 14111 13829 14175 14997>,
			<11742 13845 14126 13853 13893 14545>,
			<14583 13593 13794 13394 13690 14079>,
			<16396 13495 13516 13003 13657 13718>,
			<14361 14631 13383 12717 13886 13441>,
			<11585 15966 13406 12552 14101 13274>,
			<11354 16132 13934 12757 13903 13394>,
			<11662 16175 15030 13264 13440 13732>,
			<11806 16211 15801 13609 13350 13888>,
			<11835 16418 16464 13830 13560 13779>,
			<11850 16552 16810 14202 13895 13780>,
			<11823 16391 16755 15698 14892 15020>,
			<11753 16047 16520 17092 16044 16537>,
			<11625 15703 15881 16738 16342 16447>,
			<11250 15299 14551 15818 16457 15694>,
			<11027 14967 13959 15512 16493 15455>,
			<11066 13949 14073 15157 16421 15963>,
			<11117 13177 14257 14884 16319 16370>,
			<11114 13082 14329 14760 16123 15926>,
			<11084 12822 14489 14659 15877 15138>,
			<11063 12638 14915 15366 16009 14820>,
			<11078 12578 16142 17163 16433 14652>,
			<11132 12517 16735 17970 16711 14634>,
			<11235 12580 16446 18218 16802 15048>,
			<11366 12823 16112 18444 16905 15730>,
			<11427 13506 16311 18896 17536 16706>,
			<11447 14917 16922 19335 18655 17884>,
			<11476 15294 17048 19105 18884 18060>,
			<11566 14681 16466 18196 18585 17351>,
			<11654 14114 16042 17782 18112 16858>,
			<11631 13822 15889 17896 17019 17068>,
			<11538 14024 15901 17442 16328 17283>,
			<11521 13851 15743 16126 16601 17007>,
			<11508 12520 15133 16510 16620 16444>,
			<11478 11762 14266 16192 16577 17180>,
			<11461 11858 13255 16459 18914 18508>,
			<11647 11552 14830 15299 15447 16720>,
			<11820 11672 14539 16839 15808 16569>,
			<12097 11727 14948 15608 15787 15056>,
			<12442 12049 15179 16109 15618 14558>,
			<12885 12511 15310 15694 15176 14595>,
			<12874 12863 15508 16234 15018 15465>,
			<12331 12377 15334 16852 15139 15729>,
			<11655 11804 15099 17524 17627 17852>,
			<11380 11474 15415 17187 18253 18195>,
			<11380 11474 15415 17187 18253 18195>,
			<11380 11474 15415 17187 18253 18195>;
	};

	qcom,pc-temp-y6-lut {
		qcom,lut-col-legend = <(-10) 0 10 25 40 50>;
		qcom,lut-row-legend = <10000 9800 9600 9400 9200 9000>,
			<8800 8600 8400 8200 8000 7800>,
			<7600 7400 7200 7000 6800 6600>,
			<6400 6200 6000 5800 5600 5400>,
			<5200 5000 4800 4600 4400 4200>,
			<4000 3800 3600 3400 3200 3000>,
			<2800 2600 2400 2200 2000 1800>,
			<1600 1400 1200 1000 900 800>,
			<700 600 500 400 300 200>,
			<100 0>;
		qcom,lut-data = <6357 5509 5236 5093 5060 5056>,
			<6342 5504 5235 5092 5060 5055>,
			<6326 5501 5234 5092 5060 5055>,
			<6310 5499 5232 5092 5060 5055>,
			<6294 5499 5231 5093 5060 5055>,
			<6276 5499 5231 5093 5060 5055>,
			<6254 5502 5231 5094 5062 5055>,
			<6239 5505 5231 5095 5063 5056>,
			<6247 5504 5233 5097 5063 5057>,
			<6267 5503 5238 5100 5064 5058>,
			<6283 5511 5245 5103 5065 5059>,
			<6297 5551 5254 5107 5067 5060>,
			<6304 5572 5260 5110 5070 5062>,
			<6188 5551 5262 5112 5072 5063>,
			<6030 5518 5265 5114 5075 5065>,
			<6015 5496 5272 5121 5078 5068>,
			<6023 5476 5284 5132 5081 5071>,
			<6026 5463 5286 5144 5086 5076>,
			<6014 5455 5275 5157 5097 5083>,
			<5998 5446 5262 5163 5102 5087>,
			<5987 5431 5237 5148 5100 5086>,
			<5977 5414 5208 5126 5093 5083>,
			<5971 5405 5196 5107 5082 5075>,
			<5966 5398 5189 5090 5065 5059>,
			<5964 5394 5186 5086 5059 5053>,
			<5974 5391 5186 5085 5059 5053>,
			<5993 5389 5186 5085 5058 5053>,
			<6012 5389 5186 5085 5059 5054>,
			<6032 5388 5188 5087 5061 5055>,
			<6055 5389 5189 5089 5063 5056>,
			<6082 5392 5193 5093 5066 5059>,
			<6113 5396 5194 5096 5070 5062>,
			<6147 5404 5194 5099 5074 5066>,
			<6187 5415 5194 5101 5077 5070>,
			<6230 5427 5195 5100 5076 5069>,
			<6278 5440 5199 5099 5072 5065>,
			<6332 5455 5202 5097 5068 5061>,
			<6395 5471 5204 5092 5062 5056>,
			<6467 5488 5206 5090 5059 5054>,
			<6546 5508 5209 5090 5060 5056>,
			<6635 5531 5213 5091 5062 5058>,
			<6742 5559 5217 5093 5064 5060>,
			<6867 5586 5221 5093 5063 5058>,
			<6922 5596 5218 5093 5062 5056>,
			<7048 5649 5223 5089 5055 5049>,
			<7245 5730 5244 5096 5063 5060>,
			<7360 5787 5257 5104 5070 5070>,
			<7479 5851 5279 5113 5082 5084>,
			<7597 5928 5309 5131 5098 5097>,
			<7710 6006 5339 5138 5100 5089>,
			<7803 6083 5340 5117 5072 5065>,
			<7899 6156 5349 5119 5071 5067>,
			<8036 6317 5406 5134 5081 5076>,
			<8245 6594 5499 5162 5097 5097>,
			<8245 6594 5499 5162 5097 5097>,
			<8245 6594 5499 5162 5097 5097>;
	};
};
